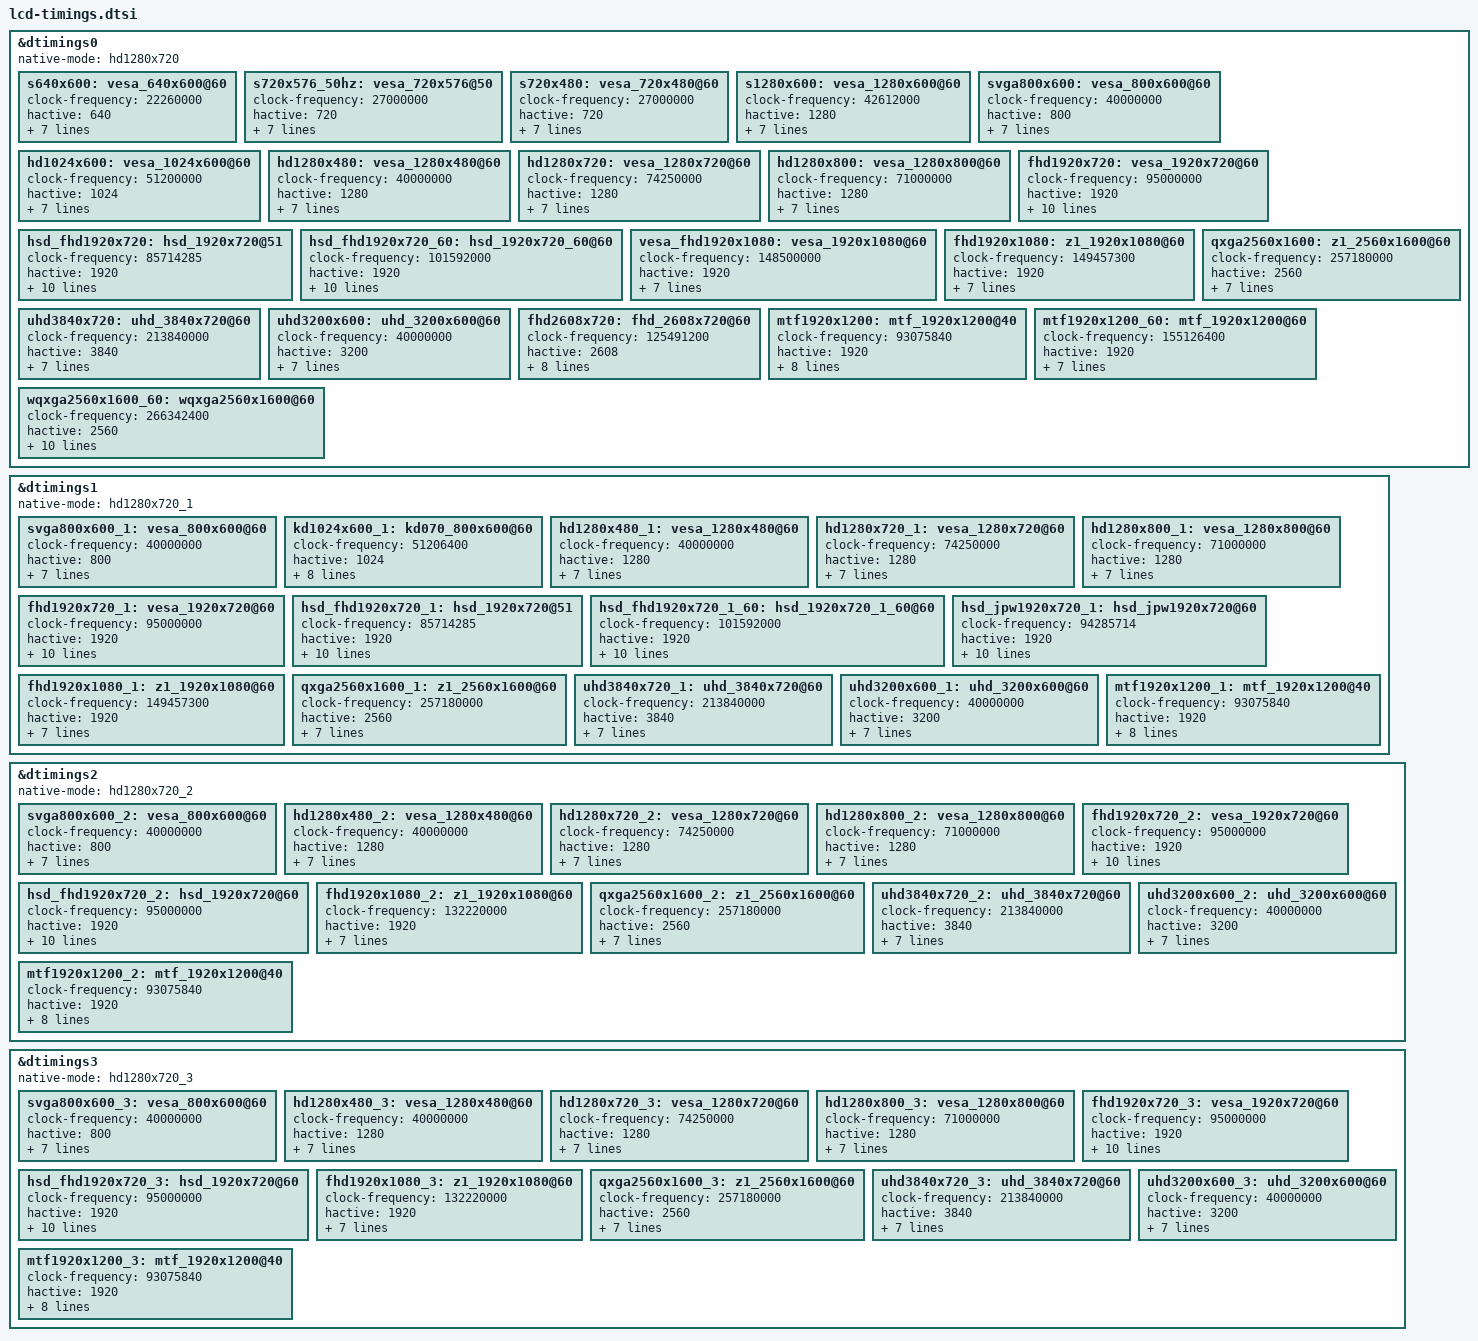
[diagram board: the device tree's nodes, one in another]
&dtimings0 {
	native-mode = <&hd1280x720>;

	s640x600: vesa_640x600@60 {
		clock-frequency = <22260000>;
		hactive = <640>;
		vactive = <600>;
		hback-porch = <20>;
		hfront-porch = <20>;
		vback-porch = <20>;
		vfront-porch = <20>;
		hsync-len = <20>;
		vsync-len = <10>;
	};

	s720x576_50hz: vesa_720x576@50 {
		clock-frequency = <27000000>;
		hactive = <720>;
		vactive = <576>;
		hback-porch = <68>;
		hfront-porch = <12>;
		vback-porch = <39>;
		vfront-porch = <5>;
		hsync-len = <64>;
		vsync-len = <5>;
	};

	s720x480: vesa_720x480@60 {
		clock-frequency = <27000000>;
		hactive = <720>;
		vactive = <480>;
		hback-porch = <60>;
		hfront-porch = <16>;
		vback-porch = <30>;
		vfront-porch = <9>;
		hsync-len = <62>;
		vsync-len = <6>;
	};

	s1280x600: vesa_1280x600@60 {
		clock-frequency = <42612000>;
		hactive = <1280>;
		vactive = <600>;
		hback-porch = <20>;
		hfront-porch = <20>;
		vback-porch = <20>;
		vfront-porch = <20>;
		hsync-len = <20>;
		vsync-len = <10>;
	};

	svga800x600: vesa_800x600@60 {
		clock-frequency = <40000000>;
		hactive = <800>;
		vactive = <600>;
		hback-porch = <88>;
		hfront-porch = <40>;
		vback-porch = <23>;
		vfront-porch = <1>;
		hsync-len = <128>;
		vsync-len = <4>;
	};

	hd1024x600: vesa_1024x600@60 {
		clock-frequency = <51200000>;
		hactive = <1024>;
		vactive = <600>;
		hback-porch = <120>;
		hfront-porch = <120>;
		vback-porch = <10>;
		vfront-porch = <10>;
		hsync-len = <80>;
		vsync-len = <15>;
	};

	hd1280x480: vesa_1280x480@60 {
		clock-frequency = <40000000>;
		hactive = <1280>;
		vactive = <480>;
		hback-porch = <220>;
		hfront-porch = <55>;
		vback-porch = <20>;
		vfront-porch = <5>;
		hsync-len = <40>;
		vsync-len = <5>;
	};

	hd1280x720: vesa_1280x720@60 {
		clock-frequency = <74250000>;
		hactive = <1280>;
		vactive = <720>;
		hback-porch = <220>;
		hfront-porch = <110>;
		vback-porch = <20>;
		vfront-porch = <5>;
		hsync-len = <40>;
		vsync-len = <5>;
	};

	hd1280x800: vesa_1280x800@60 {
		clock-frequency = <71000000>;
		hactive = <1280>;
		vactive = <800>;
		hback-porch = <80>;
		hfront-porch = <48>;
		vback-porch = <10>;
		vfront-porch = <10>;
		hsync-len = <32>;
		vsync-len = <3>;
	};

	fhd1920x720: vesa_1920x720@60 {
		clock-frequency = <95000000>;
		hactive = <1920>;
		vactive = <720>;
		hback-porch = <40>;
		hfront-porch = <40>;
		vback-porch = <50>;
		vfront-porch = <50>;
		hsync-len = <40>;
		vsync-len = <10>;
		width-mm = <292>;
		height-mm = <109>;
		vrefresh = <60>;
	};

	hsd_fhd1920x720: hsd_1920x720@51 {
		clock-frequency = <85714285>;
		hactive = <1920>;
		vactive = <720>;
		hback-porch = <40>;
		hfront-porch = <40>;
		vback-porch = <50>;
		vfront-porch = <50>;
		hsync-len = <40>;
		vsync-len = <10>;
		width-mm = <292>;
		height-mm = <109>;
		vrefresh = <51>;
	};

	hsd_fhd1920x720_60: hsd_1920x720_60@60 {
		clock-frequency = <101592000>;
		hactive = <1920>;
		vactive = <720>;
		hback-porch = <40>;
		hfront-porch = <40>;
		vback-porch = <50>;
		vfront-porch = <50>;
		hsync-len = <40>;
		vsync-len = <10>;
		width-mm = <292>;
		height-mm = <109>;
		vrefresh = <60>;
	};

	vesa_fhd1920x1080: vesa_1920x1080@60 {
		clock-frequency = <148500000>;
		hactive = <1920>;
		vactive = <1080>;
		hback-porch = <148>;
		hfront-porch = <88>;
		vback-porch = <36>;
		vfront-porch = <4>;
		hsync-len = <44>;
		vsync-len = <5>;
	};

	fhd1920x1080: z1_1920x1080@60 {
		clock-frequency = <149457300>;
		hactive = <1920>;
		vactive = <1080>;
		hback-porch = <80>;
		hfront-porch = <15>;
		vback-porch = <15>;
		vfront-porch = <80>;
		hsync-len = <80>;
		vsync-len = <14>;
	};

	qxga2560x1600: z1_2560x1600@60 {
		clock-frequency =  <257180000>;
		hactive = <2560>;
		vactive = <1600>;
		hback-porch = <20>;
		hfront-porch = <2>;
		vback-porch = <15>;
		vfront-porch = <2>;
		hsync-len = <40>;
		vsync-len = <38>;
	};

	uhd3840x720: uhd_3840x720@60 {
		clock-frequency =  <213840000>;
		hactive = <3840>;
		vactive = <720>;
		hback-porch = <200>;
		hfront-porch = <200>;
		vback-porch = <35>;
		vfront-porch = <35>;
		hsync-len = <160>;
		vsync-len = <20>;
	};
	uhd3200x600: uhd_3200x600@60 {
		clock-frequency = <40000000>;
		hactive = <3200>;
		vactive = <600>;
		hback-porch = <352>;
		hfront-porch = <160>;
		vback-porch = <23>;
		vfront-porch = <1>;
		hsync-len = <512>;
		vsync-len = <4>;
	};

	fhd2608x720: fhd_2608x720@60 {
		clock-frequency = <125491200>;
		hactive = <2608>;
		vactive = <720>;
		hback-porch = <50>;
		hfront-porch = <70>;
		vback-porch = <13>;
		vfront-porch = <17>;
		hsync-len = <24>;
		vsync-len = <10>;
		vrefresh = <45>;
	};

	mtf1920x1200: mtf_1920x1200@40 {
		clock-frequency = <93075840>;
		hactive = <1920>;
		vactive = <1200>;
		hback-porch = <12>;
		hfront-porch = <128>;
		vback-porch = <20>;
		vfront-porch = <19>;
		hsync-len = <20>;
		vsync-len = <4>;
		vrefresh = <36>;
	};

	mtf1920x1200_60: mtf_1920x1200@60 {
		clock-frequency = <155126400>;
		hactive = <1920>;
		vactive = <1200>;
		hback-porch = <12>;
		hfront-porch = <128>;
		vback-porch = <20>;
		vfront-porch = <19>;
		hsync-len = <20>;
		vsync-len = <4>;
	};

	wqxga2560x1600_60: wqxga2560x1600@60 {
		clock-frequency = <266342400>;
		hactive = <2560>;
		vactive = <1600>;
		hback-porch = <80>;
		hfront-porch = <48>;
		vback-porch = <24>;
		vfront-porch = <3>;
		hsync-len = <32>;
		vsync-len = <5>;
		vrefresh = <60>;
		width-mm = <324>;
		height-mm = <202>;
	};
};

&dtimings1 {
	native-mode = <&hd1280x720_1>;

	svga800x600_1: vesa_800x600@60 {
		clock-frequency = <40000000>;
		hactive = <800>;
		vactive = <600>;
		hback-porch = <88>;
		hfront-porch = <40>;
		vback-porch = <23>;
		vfront-porch = <1>;
		hsync-len = <128>;
		vsync-len = <4>;
	};

	kd1024x600_1: kd070_800x600@60 {
		clock-frequency = <51206400>;
		hactive = <1024>;
		vactive = <600>;
		hback-porch = <120>;
		hfront-porch = <120>;
		vback-porch = <10>;
		vfront-porch = <10>;
		hsync-len = <80>;
		vsync-len = <15>;
		vrefresh = <60>;
	};

	hd1280x480_1: vesa_1280x480@60 {
		clock-frequency = <40000000>;
		hactive = <1280>;
		vactive = <480>;
		hback-porch = <220>;
		hfront-porch = <55>;
		vback-porch = <20>;
		vfront-porch = <5>;
		hsync-len = <40>;
		vsync-len = <5>;
	};

	hd1280x720_1: vesa_1280x720@60 {
		clock-frequency = <74250000>;
		hactive = <1280>;
		vactive = <720>;
		hback-porch = <220>;
		hfront-porch = <110>;
		vback-porch = <20>;
		vfront-porch = <5>;
		hsync-len = <40>;
		vsync-len = <5>;
	};

	hd1280x800_1: vesa_1280x800@60 {
		clock-frequency = <71000000>;
		hactive = <1280>;
		vactive = <800>;
		hback-porch = <80>;
		hfront-porch = <48>;
		vback-porch = <10>;
		vfront-porch = <10>;
		hsync-len = <32>;
		vsync-len = <3>;
	};

	fhd1920x720_1: vesa_1920x720@60 {
		clock-frequency = <95000000>;
		hactive = <1920>;
		vactive = <720>;
		hback-porch = <40>;
		hfront-porch = <40>;
		vback-porch = <50>;
		vfront-porch = <50>;
		hsync-len = <40>;
		vsync-len = <10>;
		width-mm = <292>;
		height-mm = <109>;
		vrefresh = <60>;
	};

	hsd_fhd1920x720_1: hsd_1920x720@51 {
		clock-frequency = <85714285>;
		hactive = <1920>;
		vactive = <720>;
		hback-porch = <40>;
		hfront-porch = <40>;
		vback-porch = <50>;
		vfront-porch = <50>;
		hsync-len = <40>;
		vsync-len = <10>;
		width-mm = <292>;
		height-mm = <109>;
		vrefresh = <51>;
	};

	hsd_fhd1920x720_1_60: hsd_1920x720_1_60@60 {
		clock-frequency = <101592000>;
		hactive = <1920>;
		vactive = <720>;
		hback-porch = <40>;
		hfront-porch = <40>;
		vback-porch = <50>;
		vfront-porch = <50>;
		hsync-len = <40>;
		vsync-len = <10>;
		width-mm = <292>;
		height-mm = <109>;
		vrefresh = <60>;
	};

	hsd_jpw1920x720_1: hsd_jpw1920x720@60 {
		clock-frequency = <94285714>;
		hactive = <1920>;
		hfront-porch = <52>;
		hback-porch = <32>;
		hsync-len = <24>;
		vactive = <720>;
		vfront-porch = <8>;
		vback-porch = <21>;
		vsync-len = <3>;
		width-mm = <292>;
		height-mm = <109>;
		vrefresh = <60>;
	};

	fhd1920x1080_1: z1_1920x1080@60 {
		clock-frequency = <149457300>;
		hactive = <1920>;
		vactive = <1080>;
		hback-porch = <80>;
		hfront-porch = <15>;
		vback-porch = <15>;
		vfront-porch = <80>;
		hsync-len = <80>;
		vsync-len = <14>;
	};

	qxga2560x1600_1: z1_2560x1600@60 {
		clock-frequency =  <257180000>;
		hactive = <2560>;
		vactive = <1600>;
		hback-porch = <20>;
		hfront-porch = <2>;
		vback-porch = <15>;
		vfront-porch = <2>;
		hsync-len = <40>;
		vsync-len = <38>;
	};

	uhd3840x720_1: uhd_3840x720@60 {
		clock-frequency =  <213840000>;
		hactive = <3840>;
		vactive = <720>;
		hback-porch = <200>;
		hfront-porch = <200>;
		vback-porch = <35>;
		vfront-porch = <35>;
		hsync-len = <160>;
		vsync-len = <20>;
	};
	uhd3200x600_1: uhd_3200x600@60 {
		clock-frequency = <40000000>;
		hactive = <3200>;
		vactive = <600>;
		hback-porch = <352>;
		hfront-porch = <160>;
		vback-porch = <23>;
		vfront-porch = <1>;
		hsync-len = <512>;
		vsync-len = <4>;
	};

	mtf1920x1200_1: mtf_1920x1200@40 {
		clock-frequency = <93075840>;
		hactive = <1920>;
		vactive = <1200>;
		hback-porch = <12>;
		hfront-porch = <128>;
		vback-porch = <20>;
		vfront-porch = <19>;
		hsync-len = <20>;
		vsync-len = <4>;
		vrefresh = <36>;
	};
};

&dtimings2 {
	native-mode = <&hd1280x720_2>;

	svga800x600_2: vesa_800x600@60 {
		clock-frequency = <40000000>;
		hactive = <800>;
		vactive = <600>;
		hback-porch = <88>;
		hfront-porch = <40>;
		vback-porch = <23>;
		vfront-porch = <1>;
		hsync-len = <128>;
		vsync-len = <4>;
	};

	hd1280x480_2: vesa_1280x480@60 {
		clock-frequency = <40000000>;
		hactive = <1280>;
		vactive = <480>;
		hback-porch = <220>;
		hfront-porch = <55>;
		vback-porch = <20>;
		vfront-porch = <5>;
		hsync-len = <40>;
		vsync-len = <5>;
	};

	hd1280x720_2: vesa_1280x720@60 {
		clock-frequency = <74250000>;
		hactive = <1280>;
		vactive = <720>;
		hback-porch = <220>;
		hfront-porch = <110>;
		vback-porch = <20>;
		vfront-porch = <5>;
		hsync-len = <40>;
		vsync-len = <5>;
	};

	hd1280x800_2: vesa_1280x800@60 {
		clock-frequency = <71000000>;
		hactive = <1280>;
		vactive = <800>;
		hback-porch = <80>;
		hfront-porch = <48>;
		vback-porch = <10>;
		vfront-porch = <10>;
		hsync-len = <32>;
		vsync-len = <3>;
	};

	fhd1920x720_2: vesa_1920x720@60 {
		clock-frequency = <95000000>;
		hactive = <1920>;
		vactive = <720>;
		hback-porch = <50>;
		hfront-porch = <50>;
		vback-porch = <15>;
		vfront-porch = <15>;
		hsync-len = <60>;
		vsync-len = <10>;
		width-mm = <292>;
		height-mm = <109>;
		vrefresh = <60>;
	};

	hsd_fhd1920x720_2: hsd_1920x720@60 {
		clock-frequency = <95000000>;
		hactive = <1920>;
		vactive = <720>;
		hback-porch = <40>;
		hfront-porch = <40>;
		vback-porch = <50>;
		vfront-porch = <50>;
		hsync-len = <40>;
		vsync-len = <10>;
		width-mm = <292>;
		height-mm = <109>;
		vrefresh = <60>;
	};

	fhd1920x1080_2: z1_1920x1080@60 {
		clock-frequency = <132220000>;
		hactive = <1920>;
		vactive = <1080>;
		hback-porch = <1>;
		hfront-porch = <39>;
		vback-porch = <1>;
		vfront-porch = <20>;
		hsync-len = <20>;
		vsync-len = <12>;
	};

	qxga2560x1600_2: z1_2560x1600@60 {
		clock-frequency =  <257180000>;
		hactive = <2560>;
		vactive = <1600>;
		hback-porch = <20>;
		hfront-porch = <2>;
		vback-porch = <15>;
		vfront-porch = <2>;
		hsync-len = <40>;
		vsync-len = <38>;
	};

	uhd3840x720_2: uhd_3840x720@60 {
		clock-frequency =  <213840000>;
		hactive = <3840>;
		vactive = <720>;
		hback-porch = <200>;
		hfront-porch = <200>;
		vback-porch = <35>;
		vfront-porch = <35>;
		hsync-len = <160>;
		vsync-len = <20>;
	};
	uhd3200x600_2: uhd_3200x600@60 {
		clock-frequency = <40000000>;
		hactive = <3200>;
		vactive = <600>;
		hback-porch = <352>;
		hfront-porch = <160>;
		vback-porch = <23>;
		vfront-porch = <1>;
		hsync-len = <512>;
		vsync-len = <4>;
	};

	mtf1920x1200_2: mtf_1920x1200@40 {
		clock-frequency = <93075840>;
		hactive = <1920>;
		vactive = <1200>;
		hback-porch = <12>;
		hfront-porch = <128>;
		vback-porch = <20>;
		vfront-porch = <19>;
		hsync-len = <20>;
		vsync-len = <4>;
		vrefresh = <36>;
	};
};

&dtimings3 {
	native-mode = <&hd1280x720_3>;

	svga800x600_3: vesa_800x600@60 {
		clock-frequency = <40000000>;
		hactive = <800>;
		vactive = <600>;
		hback-porch = <88>;
		hfront-porch = <40>;
		vback-porch = <23>;
		vfront-porch = <1>;
		hsync-len = <128>;
		vsync-len = <4>;
	};

	hd1280x480_3: vesa_1280x480@60 {
		clock-frequency = <40000000>;
		hactive = <1280>;
		vactive = <480>;
		hback-porch = <220>;
		hfront-porch = <55>;
		vback-porch = <20>;
		vfront-porch = <5>;
		hsync-len = <40>;
		vsync-len = <5>;
	};

	hd1280x720_3: vesa_1280x720@60 {
		clock-frequency = <74250000>;
		hactive = <1280>;
		vactive = <720>;
		hback-porch = <220>;
		hfront-porch = <110>;
		vback-porch = <20>;
		vfront-porch = <5>;
		hsync-len = <40>;
		vsync-len = <5>;
	};

	hd1280x800_3: vesa_1280x800@60 {
		clock-frequency = <71000000>;
		hactive = <1280>;
		vactive = <800>;
		hback-porch = <80>;
		hfront-porch = <48>;
		vback-porch = <10>;
		vfront-porch = <10>;
		hsync-len = <32>;
		vsync-len = <3>;
	};

	fhd1920x720_3: vesa_1920x720@60 {
		clock-frequency = <95000000>;
		hactive = <1920>;
		vactive = <720>;
		hback-porch = <50>;
		hfront-porch = <50>;
		vback-porch = <15>;
		vfront-porch = <15>;
		hsync-len = <60>;
		vsync-len = <10>;
		width-mm = <292>;
		height-mm = <109>;
		vrefresh = <60>;
	};

	hsd_fhd1920x720_3: hsd_1920x720@60 {
		clock-frequency = <95000000>;
		hactive = <1920>;
		vactive = <720>;
		hback-porch = <40>;
		hfront-porch = <40>;
		vback-porch = <50>;
		vfront-porch = <50>;
		hsync-len = <40>;
		vsync-len = <10>;
		width-mm = <292>;
		height-mm = <109>;
		vrefresh = <60>;
	};

	fhd1920x1080_3: z1_1920x1080@60 {
		clock-frequency = <132220000>;
		hactive = <1920>;
		vactive = <1080>;
		hback-porch = <1>;
		hfront-porch = <39>;
		vback-porch = <1>;
		vfront-porch = <20>;
		hsync-len = <20>;
		vsync-len = <12>;
	};

	qxga2560x1600_3: z1_2560x1600@60 {
		clock-frequency =  <257180000>;
		hactive = <2560>;
		vactive = <1600>;
		hback-porch = <20>;
		hfront-porch = <2>;
		vback-porch = <15>;
		vfront-porch = <2>;
		hsync-len = <40>;
		vsync-len = <38>;
	};

	uhd3840x720_3: uhd_3840x720@60 {
		clock-frequency =  <213840000>;
		hactive = <3840>;
		vactive = <720>;
		hback-porch = <200>;
		hfront-porch = <200>;
		vback-porch = <35>;
		vfront-porch = <35>;
		hsync-len = <160>;
		vsync-len = <20>;
	};
	uhd3200x600_3: uhd_3200x600@60 {
		clock-frequency = <40000000>;
		hactive = <3200>;
		vactive = <600>;
		hback-porch = <352>;
		hfront-porch = <160>;
		vback-porch = <23>;
		vfront-porch = <1>;
		hsync-len = <512>;
		vsync-len = <4>;
	};

	mtf1920x1200_3: mtf_1920x1200@40 {
		clock-frequency = <93075840>;
		hactive = <1920>;
		vactive = <1200>;
		hback-porch = <12>;
		hfront-porch = <128>;
		vback-porch = <20>;
		vfront-porch = <19>;
		hsync-len = <20>;
		vsync-len = <4>;
		vrefresh = <36>;
	};
};
